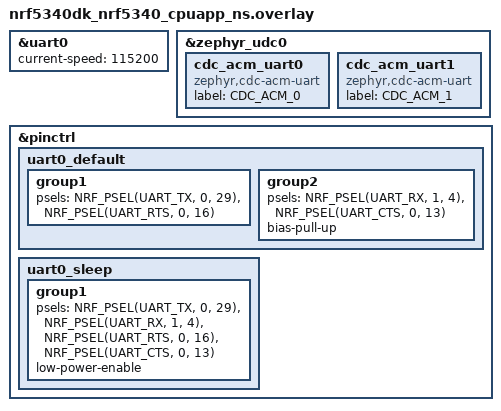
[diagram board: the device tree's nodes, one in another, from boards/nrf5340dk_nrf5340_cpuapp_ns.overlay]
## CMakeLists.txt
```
#
# Copyright (c) 2020 Nordic Semiconductor
#
# SPDX-License-Identifier: LicenseRef-Nordic-5-Clause
#

cmake_minimum_required(VERSION 3.20.0)

find_package(Zephyr REQUIRED HINTS $ENV{ZEPHYR_BASE})
find_package(Git)
project(NONE)

# NORDIC SDK APP START
target_sources(app PRIVATE src/main.c)
# NORDIC SDK APP END

# Generate a C header file with the readme text as a string variable
set(OUTPUT_README_HEADER_FILE "${CMAKE_BINARY_DIR}/generated/readme/readme.h")
set(INPUT_README_FILE ${CMAKE_SOURCE_DIR}/boards/${NORMALIZED_BOARD_TARGET}_readme.txt)

if(NOT EXISTS ${INPUT_README_FILE})
  message(WARNING "${INPUT_README_FILE} does not exist")
  set(INPUT_README_FILE ${CMAKE_SOURCE_DIR}/README_TEMPLATE.txt)
endif()

file(READ ${INPUT_README_FILE} README_CONTENT)
if(GIT_FOUND)
  execute_process(
        COMMAND ${GIT_EXECUTABLE} rev-parse --short HEAD
        WORKING_DIRECTORY ${CMAKE_SOURCE_DIR}
        OUTPUT_VARIABLE GIT_HASH
        OUTPUT_STRIP_TRAILING_WHITESPACE
  )
  string(TIMESTAMP CURRENT_DATE "%Y-%m-%d")
  string(APPEND README_CONTENT "\nFirmware version: ${GIT_HASH} Build date: ${CURRENT_DATE}\n")
endif()
string(REPLACE "\"" "\\\"" README_CONTENT "${README_CONTENT}")
string(REPLACE "\n" "\\n\"\n\"" README_CONTENT "${README_CONTENT}")
file(WRITE ${OUTPUT_README_HEADER_FILE} "\"${README_CONTENT}\"")


# Include application events and disk files
zephyr_library_include_directories(
  src/events
  ${CMAKE_BINARY_DIR}/generated/readme
  )

# Application sources
add_subdirectory(src/disk)
add_subdirectory(src/events)
add_subdirectory(src/modules)
```

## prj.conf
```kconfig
# General
CONFIG_REBOOT=y
CONFIG_HEAP_MEM_POOL_SIZE=8192
CONFIG_SYSTEM_WORKQUEUE_STACK_SIZE=2048
CONFIG_MAIN_STACK_SIZE=2048
CONFIG_GPIO=y
CONFIG_POLL=y
CONFIG_BOOTLOADER_MCUBOOT=y
CONFIG_APP_EVENT_MANAGER=y
CONFIG_SPEED_OPTIMIZATIONS=y
CONFIG_PM_DEVICE=y

# Features
CONFIG_BRIDGE_CDC_ENABLE=y
CONFIG_BRIDGE_MSC_ENABLE=y
CONFIG_BRIDGE_BLE_ENABLE=y

 # USB
CONFIG_USB_DEVICE_STACK=y
CONFIG_USB_DEVICE_REMOTE_WAKEUP=n
CONFIG_USB_DEVICE_MANUFACTURER="Nordic Semiconductor"
CONFIG_USB_DEVICE_SN="THINGY91 12PLACEHLDRS" # This is overridden at runtime
CONFIG_USB_COMPOSITE_DEVICE=y
CONFIG_USB_CDC_ACM_RINGBUF_SIZE=16384

# Disk and file system
CONFIG_DISK_ACCESS=y
CONFIG_DISK_DRIVER_RAM=y
CONFIG_FILE_SYSTEM=y
CONFIG_FAT_FILESYSTEM_ELM=y
CONFIG_FS_FATFS_LFN=y

# Settings
CONFIG_FCB=y
CONFIG_SETTINGS=y
CONFIG_SETTINGS_FCB=y
CONFIG_FLASH=y
CONFIG_FLASH_PAGE_LAYOUT=y
CONFIG_FLASH_MAP=y
CONFIG_MPU_ALLOW_FLASH_WRITE=y

# Logging
CONFIG_LOG=y
CONFIG_USE_SEGGER_RTT=y
CONFIG_LOG_BACKEND_RTT=y
CONFIG_LOG_BACKEND_RTT_MODE_DROP=y

# Event logs
CONFIG_BRIDGE_LOG_MODULE_STATE_EVENT=n
CONFIG_BRIDGE_LOG_UART_DATA_EVENT=n
CONFIG_BRIDGE_LOG_CDC_DATA_EVENT=n
CONFIG_BRIDGE_LOG_BLE_DATA_EVENT=n
CONFIG_BRIDGE_LOG_BLE_CTRL_EVENT=n
CONFIG_BRIDGE_LOG_PEER_CONN_EVENT=n
CONFIG_BRIDGE_LOG_FS_EVENT=n
CONFIG_BRIDGE_LOG_POWER_DOWN_EVENT=n

 # UART
CONFIG_SERIAL=y
CONFIG_UART_INTERRUPT_DRIVEN=y
CONFIG_UART_0_INTERRUPT_DRIVEN=n
CONFIG_UART_1_INTERRUPT_DRIVEN=n
CONFIG_UART_LINE_CTRL=y
CONFIG_UART_ASYNC_API=y
CONFIG_UART_0_ASYNC=y
CONFIG_UART_1_ASYNC=y
CONFIG_UART_0_NRF_HW_ASYNC=y
CONFIG_UART_1_NRF_HW_ASYNC=y
CONFIG_UART_0_NRF_HW_ASYNC_TIMER=1
CONFIG_UART_1_NRF_HW_ASYNC_TIMER=2
CONFIG_UART_USE_RUNTIME_CONFIGURE=y
CONFIG_NRFX_UARTE0=y
CONFIG_NRFX_UARTE1=y
CONFIG_NRFX_TIMER1=y
CONFIG_NRFX_TIMER2=y
CONFIG_NRFX_PPI=y

# Bootloader firmware information
CONFIG_FW_INFO=y
CONFIG_SECURE_BOOT_STORAGE=y

CONFIG_HW_ID_LIBRARY=y
```

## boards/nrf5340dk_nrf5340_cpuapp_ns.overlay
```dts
&uart0 {
	status = "okay";
	current-speed = <115200>;
};

&zephyr_udc0 {
	cdc_acm_uart0: cdc_acm_uart0 {
		compatible = "zephyr,cdc-acm-uart";
		label = "CDC_ACM_0";
	};

	cdc_acm_uart1: cdc_acm_uart1 {
		compatible = "zephyr,cdc-acm-uart";
		label = "CDC_ACM_1";
	};
};

&pinctrl {
	uart0_default: uart0_default {
		group1 {
			psels = <NRF_PSEL(UART_TX, 0, 29)>,
				<NRF_PSEL(UART_RTS, 0, 16)>;
		};
		group2 {
			psels = <NRF_PSEL(UART_RX, 1, 4)>,
				<NRF_PSEL(UART_CTS, 0, 13)>;
			bias-pull-up;
		};
	};

	uart0_sleep: uart0_sleep {
		group1 {
			psels = <NRF_PSEL(UART_TX, 0, 29)>,
				<NRF_PSEL(UART_RX, 1, 4)>,
				<NRF_PSEL(UART_RTS, 0, 16)>,
				<NRF_PSEL(UART_CTS, 0, 13)>;
			low-power-enable;
		};
	};
};
```

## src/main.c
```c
/*
 * Copyright (c) 2020 Nordic Semiconductor ASA
 *
 * SPDX-License-Identifier: LicenseRef-Nordic-5-Clause
 */

#include <zephyr/kernel.h>


#include <app_event_manager.h>
#include <drivers/hwinfo.h>

#define MODULE main
#include "module_state_event.h"

#include <zephyr/logging/log.h>
LOG_MODULE_REGISTER(MODULE);

#define USB_SERIALNUMBER_TEMPLATE "THINGY91_%04X%08X"

static uint8_t usb_serial_str[] = "THINGY91_12PLACEHLDRS";

/* Overriding weak function to set iSerialNumber at runtime. */
uint8_t *usb_update_sn_string_descriptor(void)
{
	uint32_t hwid[2];
	int hwlen;

	memset(hwid, 0, sizeof(hwid));

	hwlen = hwinfo_get_device_id((uint8_t *)hwid, sizeof(hwid));
	if (hwlen > 0) {
		snprintk(usb_serial_str, sizeof(usb_serial_str), USB_SERIALNUMBER_TEMPLATE,
					(hwid[1] & 0x0000FFFF)|0x0000C000,
					hwid[0]);
	}

	return usb_serial_str;
}

void main(void)
{
	if (app_event_manager_init()) {
		LOG_ERR("Application Event Manager not initialized");
	} else {
		module_set_state(MODULE_STATE_READY);
	}
}
```
